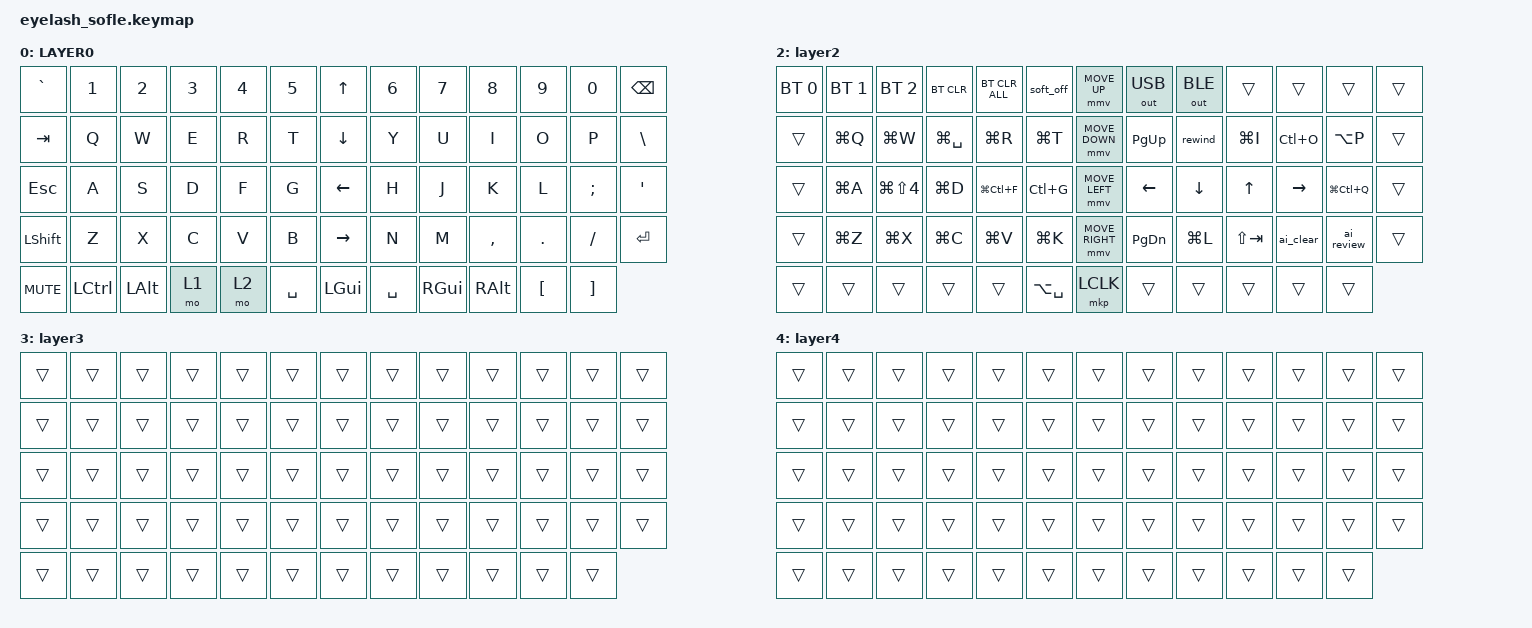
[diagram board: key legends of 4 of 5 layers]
#define ZMK_POINTING_DEFAULT_MOVE_VAL 1200  // 600
#define ZMK_POINTING_DEFAULT_SCRL_VAL 25   // 10

#include <input/processors.dtsi>
#include <zephyr/dt-bindings/input/input-event-codes.h>
#include <behaviors.dtsi>
#include <dt-bindings/zmk/bt.h>
#include <dt-bindings/zmk/keys.h>
#include <dt-bindings/zmk/outputs.h>
#include <dt-bindings/zmk/pointing.h>
#include <dt-bindings/zmk/rgb.h>
#include <dt-bindings/zmk/rgb_fx.h>
#include "eyelash_sofle_rgb_fx.dtsi"

&led_strip {
    chain-length = <7>;
};

&mmv_input_listener { input-processors = <&zip_xy_scaler 2 1>; };

&msc_input_listener { input-processors = <&zip_scroll_scaler 2 1>; };

&msc {
    acceleration-exponent = <1>;      // 0
    time-to-max-speed-ms = <100>;       // 300
    delay-ms = <0>;                   // 0
};

&mmv {
    time-to-max-speed-ms = <500>;
    acceleration-exponent = <1>;
    trigger-period-ms = <16>;
};

&soft_off { hold-time-ms = <2000>; };

/ {
    scroll_encoder: scroll_encoder {
        compatible = "zmk,behavior-sensor-rotate";
        #sensor-binding-cells = <0>;
        bindings = <&msc SCRL_DOWN>, <&msc SCRL_UP>;

        tap-ms = <100>;
    };

    behaviors {
    };

    combos {
        compatible = "zmk,combos";

        softoff {
            bindings = <&soft_off>;
            key-positions = <14 28 40>;
        };
    };

    macros {
        SHIFT_MCLK: SHIFT_MCLK {
            compatible = "zmk,behavior-macro";
            #binding-cells = <0>;
            bindings =
                <&macro_press>,
                <&kp LEFT_SHIFT>,
                <&macro_press>,
                <&mkp MB3>,
                <&macro_pause_for_release>,
                <&macro_release>,
                <&kp LEFT_SHIFT &mkp MB3>;

            label = "SHIFT_MCLK";
        };

        rewind: rewind {
            compatible = "zmk,behavior-macro";
            #binding-cells = <0>;
            bindings = <&kp ESC &kp ESC>;
            label = "rewind";
        };

        ai_clear: ai_clear {
            compatible = "zmk,behavior-macro";
            #binding-cells = <0>;
            bindings = <&kp FSLH &kp C &kp L &kp E &kp A &kp R &kp ENTER>;
            label = "ai_clear";
        };

        ai_review: ai_review {
            compatible = "zmk,behavior-macro";
            #binding-cells = <0>;
            bindings = <&kp FSLH &kp R &kp E &kp V &kp I &kp E &kp W &kp ENTER>;
            label = "ai_review";
        };

        /* Theme macros removed - using &rgbfx RGBFX_SELECT directly */
    };

    keymap {
        compatible = "zmk,keymap";

        layer0 {
            bindings = <
&kp GRAVE   &kp N1     &kp N2    &kp N3    &kp N4    &kp N5       &kp UP_ARROW     &kp N6     &kp N7    &kp N8     &kp N9    &kp N0      &kp BACKSPACE
&kp TAB     &kp Q      &kp W     &kp E     &kp R     &kp T        &kp DOWN_ARROW   &kp Y      &kp U     &kp I      &kp O     &kp P       &kp BSLH
&kp ESC     &kp A      &kp S     &kp D     &kp F     &kp G        &kp LEFT_ARROW   &kp H      &kp J     &kp K      &kp L     &kp SEMI    &kp APOS
&kp LSHFT   &kp Z      &kp X     &kp C     &kp V     &kp B        &kp RIGHT_ARROW  &kp N      &kp M     &kp COMMA  &kp DOT   &kp FSLH    &kp ENTER
&kp C_MUTE  &kp LCTRL  &kp LALT  &mo 1     &mo 2     &kp SPACE    &kp LGUI         &kp SPACE  &kp RGUI  &kp RALT   &kp LBKT  &kp RBKT
            >;

            sensor-bindings = <&inc_dec_kp C_VOLUME_UP C_VOL_DN>;
            display-name = "LAYER0";
        };

        layer_1 {
            bindings = <
&kp GRAVE   &kp F1                    &kp F2                    &kp F3                  &kp F4                  &kp F5                      &mmv MOVE_UP     &rgbfx RGBFX_SELECT(0,0)  &rgbfx RGBFX_SELECT(0,1)  &rgbfx RGBFX_SELECT(0,2)  &kp F9           &kp F10          &trans
&trans      &rgbfx RGBFX_TOGGLE(0)    &rgbfx RGBFX_NEXT(0)     &rgbfx RGBFX_BRIGHTEN(0) &trans                  &trans                      &mmv MOVE_DOWN   &trans                    &kp C_PREV                &kp C_PP                  &kp C_NEXT       &trans           &trans
&trans      &trans                    &rgbfx RGBFX_PREVIOUS(0)  &rgbfx RGBFX_DIM(0)     &trans                  &trans                      &mmv MOVE_LEFT   &trans                    &kp C_MUTE                &kp C_VOL_DN              &kp C_VOL_UP     &trans           &trans
&trans      &trans                    &trans                    &trans                  &trans                  &trans                      &mmv MOVE_RIGHT  &trans                    &trans                    &trans                    &trans           &trans           &trans
&kp C_MUTE  &trans                    &trans                    &trans                  &trans                  &trans                      &mkp LCLK        &trans                    &trans                    &trans                    &trans           &trans
            >;

            display-name = "layer1";
            sensor-bindings = <&scroll_encoder>;
        };

        layer_2 {
            bindings = <
&bt BT_SEL 0 &bt BT_SEL 1    &bt BT_SEL 2    &bt BT_CLR      &bt BT_CLR_ALL  &soft_off          &mmv MOVE_UP     &out OUT_USB    &out OUT_BLE     &trans           &trans           &trans           &trans
&trans      &kp LG(Q)       &kp LG(W)       &kp LG(SPACE)   &kp LG(R)       &kp LG(T)          &mmv MOVE_DOWN   &kp PG_UP        &rewind          &kp LG(I)        &kp LC(O)        &kp LA(P)        &trans
&trans      &kp LG(A)       &kp LG(LS(N4))  &kp LG(D)       &kp LG(LC(F))   &kp LC(G)          &mmv MOVE_LEFT   &kp LEFT         &kp DOWN         &kp UP           &kp RIGHT        &kp LG(LC(Q))    &trans
&trans      &kp LG(Z)       &kp LG(X)       &kp LG(C)       &kp LG(V)       &kp LG(K)          &mmv MOVE_RIGHT  &kp PG_DN        &kp LG(L)        &kp LS(TAB)      &ai_clear        &ai_review       &trans
&trans      &trans          &trans          &trans          &trans          &kp LA(SPACE)      &mkp LCLK        &trans           &trans           &trans           &trans           &trans
            >;

            display-name = "layer2";
            sensor-bindings = <&scroll_encoder>;
        };

        layer_3 {
            bindings = <
&trans  &trans  &trans  &trans  &trans  &trans    &trans  &trans  &trans  &trans  &trans  &trans  &trans
&trans  &trans  &trans  &trans  &trans  &trans    &trans  &trans  &trans  &trans  &trans  &trans  &trans
&trans  &trans  &trans  &trans  &trans  &trans    &trans  &trans  &trans  &trans  &trans  &trans  &trans
&trans  &trans  &trans  &trans  &trans  &trans    &trans  &trans  &trans  &trans  &trans  &trans  &trans
&trans  &trans  &trans  &trans  &trans  &trans    &trans  &trans  &trans  &trans  &trans  &trans
            >;

            display-name = "layer3";
            sensor-bindings = <&scroll_encoder>;
        };

        layer_4 {
            bindings = <
&trans  &trans  &trans  &trans  &trans  &trans    &trans  &trans  &trans  &trans  &trans  &trans  &trans
&trans  &trans  &trans  &trans  &trans  &trans    &trans  &trans  &trans  &trans  &trans  &trans  &trans
&trans  &trans  &trans  &trans  &trans  &trans    &trans  &trans  &trans  &trans  &trans  &trans  &trans
&trans  &trans  &trans  &trans  &trans  &trans    &trans  &trans  &trans  &trans  &trans  &trans  &trans
&trans  &trans  &trans  &trans  &trans  &trans    &trans  &trans  &trans  &trans  &trans  &trans
            >;

            display-name = "layer4";
            sensor-bindings = <&scroll_encoder>;
        };
    };
};
